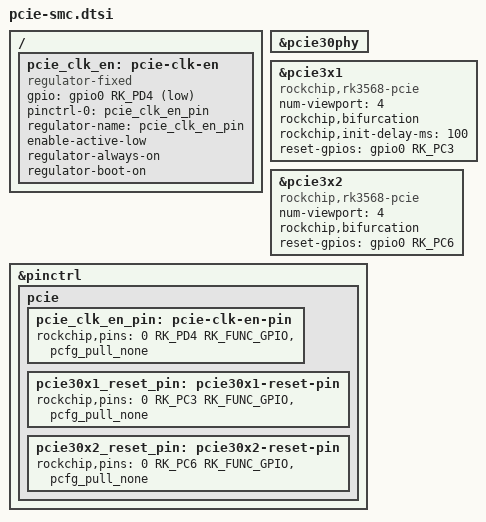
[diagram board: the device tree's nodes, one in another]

/ {
/*
	This is dummy regulator.
	It is used to have ability to activate PCIE clock source for RK3568J SoC
	1V8_PCIE_PWREN_ -> D18
*/
	pcie_clk_en: pcie-clk-en {
		compatible = "regulator-fixed";
		gpio = <&gpio0 RK_PD4 GPIO_ACTIVE_LOW>;
		pinctrl-names = "default";
		pinctrl-0 = <&pcie_clk_en_pin>;
		regulator-name = "pcie_clk_en_pin";
		enable-active-low;
		regulator-always-on;
		regulator-boot-on;
    };

/*
	PCIE30X1_PERSTn -> D3 -> PCIe1_RST_
	0 -> 0
	1 -> 1
*/
/*    pcie30x1_reset: pcie30x1-reset {
		compatible = "regulator-fixed";
		regulator-name = "pcie30x1_reset";
		gpio = <&gpio0 RK_PC3 GPIO_ACTIVE_HIGH>;
		pinctrl-names = "default";
		pinctrl-0 = <&pcie30x1_reset_pin>;
		enable-active-high;
		regulator-always-on;
		regulator-boot-on;
	};*/

/*
	PCIE30X2_PERSTn -> D4 -> PCIe2_RST_
	0 -> 0
	1 -> 1
*/
/*    pcie30x2_reset: pcie30x2-reset {
		compatible = "regulator-fixed";
		regulator-name = "pcie30x2_reset";
		gpio = <&gpio0 RK_PC6 GPIO_ACTIVE_HIGH>;
		pinctrl-names = "default";
		pinctrl-0 = <&pcie30x2_reset_pin>;
		enable-active-high;
		regulator-always-on;
		regulator-boot-on;
	};*/
};

&pcie30phy {
	status = "okay";
};

/*
	This controller has one lane 0.
	The lane 0 is connected to PCIE_A pins on SMARC connector X1.
	If bifurcation mode is cativated the lane 0 is controlled by pcie3x1.
*/
&pcie3x1 {
    compatible = "rockchip,rk3568-pcie";
	num-viewport = <4>;
	rockchip,bifurcation;
	rockchip,init-delay-ms = <100>;
	reset-gpios = <&gpio0 RK_PC3 GPIO_ACTIVE_HIGH>;

	status = "okay";
};

/*
	This controller has two lanes which can be organized in PCIE2x mode or in case of enabled bifurcation in PCIE1x mode.
	The lane 0 is connected to PCIE_B pins on SMARC connector X1.
	If bifurcation mode is cativated the lane 1 is controlled by pcie3x1, lane 0 is controlled by pcie3x2
*/
&pcie3x2 {
    compatible = "rockchip,rk3568-pcie";
	num-viewport = <4>;
	rockchip,bifurcation;
	reset-gpios = <&gpio0 RK_PC6 GPIO_ACTIVE_HIGH>;

	status = "okay";
};

&pinctrl {
	pcie {
		pcie_clk_en_pin: pcie-clk-en-pin {
/*
			1V8_PCIE_PWREN -> D18 -> PCIe_REF_EN
			0 -> 0
			1 -> 1
*/
			rockchip,pins = <0 RK_PD4 RK_FUNC_GPIO &pcfg_pull_none>;
		};

		pcie30x1_reset_pin: pcie30x1-reset-pin {
/*
			PCIE30X1_PERSTn -> D3 -> PCIe1_RST_
			0 -> 0
			1 -> 1
*/
			rockchip,pins = <0 RK_PC3 RK_FUNC_GPIO &pcfg_pull_none>;
		};

		pcie30x2_reset_pin: pcie30x2-reset-pin {
/*
			PCIE30X2_PERSTn -> D4 -> PCIe2_RST_
			0 -> 0
			1 -> 1
*/
			rockchip,pins = <0 RK_PC6 RK_FUNC_GPIO &pcfg_pull_none>;
		};
	};
};

